VERSION ""

NS_ :

BS_:

BU_: ECM TCU BCM

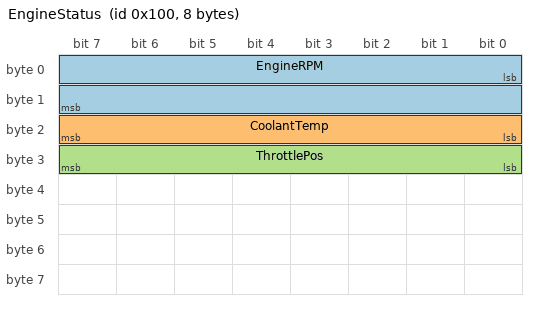
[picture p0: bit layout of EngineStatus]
BO_ 256 EngineStatus: 8 ECM
 SG_ EngineRPM : 0|16@1+ (0.25,0) [0|8000] "rpm" TCU,BCM
 SG_ CoolantTemp : 16|8@1+ (1,-40) [-40|215] "degC" BCM
 SG_ ThrottlePos : 24|8@1+ (0.4,0) [0|100] "%" TCU

BO_ 512 TransmissionStatus: 8 TCU
 SG_ GearPosition : 0|4@1+ (1,0) [0|15] "" ECM
 SG_ TorqueReq : 8|16@1+ (0.1,0) [0|500] "Nm" ECM

BO_ 1024 BodyControl: 4 BCM
 SG_ HeadlightState : 0|2@1+ (1,0) [0|3] "" ECM
 SG_ WiperState : 2|2@1+ (1,0) [0|3] "" ECM

BA_DEF_ BO_ "GenMsgCycleTime" INT 0 10000;

BA_DEF_DEF_ "GenMsgCycleTime" 0;

BA_ "GenMsgCycleTime" BO_ 256 10;
BA_ "GenMsgCycleTime" BO_ 512 20;

CM_ BU_ ECM "Engine Control Module";
CM_ BU_ TCU "Transmission Control Unit";
CM_ BO_ 256 "Engine operating status signals";
CM_ SG_ 256 EngineRPM "Current engine speed in RPM";
CM_ SG_ 256 CoolantTemp "Engine coolant temperature";
